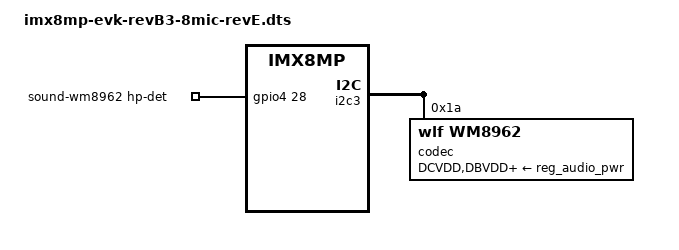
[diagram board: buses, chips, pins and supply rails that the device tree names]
// SPDX-License-Identifier: GPL-2.0+
/*
 * Copyright 2023 NXP
 */

#include "imx8mp-evk-revA3-8mic-revE.dts"

/delete-node/ &codec;

/ {
	/delete-node/ sound-wm8960;

	sound-wm8962 {
		compatible = "fsl,imx-audio-wm8962";
		model = "wm8962-audio";
		audio-cpu = <&sai3>;
		audio-codec = <&codec>;
		audio-asrc = <&easrc>;
		hp-det-gpio = <&gpio4 28 0>;
		audio-routing =
			"Headphone Jack", "HPOUTL",
			"Headphone Jack", "HPOUTR",
			"Ext Spk", "SPKOUTL",
			"Ext Spk", "SPKOUTR",
			"AMIC", "MICBIAS",
			"IN1R", "AMIC",
			"IN1L", "AMIC";
	};
};

&i2c3 {
	codec: wm8962@1a {
		compatible = "wlf,wm8962";
		reg = <0x1a>;
		clocks = <&audio_blk_ctrl IMX8MP_CLK_AUDIOMIX_SAI3_MCLK1>;
		DCVDD-supply = <&reg_audio_pwr>;
		DBVDD-supply = <&reg_audio_pwr>;
		AVDD-supply = <&reg_audio_pwr>;
		CPVDD-supply = <&reg_audio_pwr>;
		MICVDD-supply = <&reg_audio_pwr>;
		PLLVDD-supply = <&reg_audio_pwr>;
		SPKVDD1-supply = <&reg_audio_pwr>;
		SPKVDD2-supply = <&reg_audio_pwr>;
		gpio-cfg = <
			0x0000 /* 0:Default */
			0x0000 /* 1:Default */
			0x0000 /* 2:FN_DMICCLK */
			0x0000 /* 3:Default */
			0x0000 /* 4:FN_DMICCDAT */
			0x0000 /* 5:Default */
		>;
	};
};
